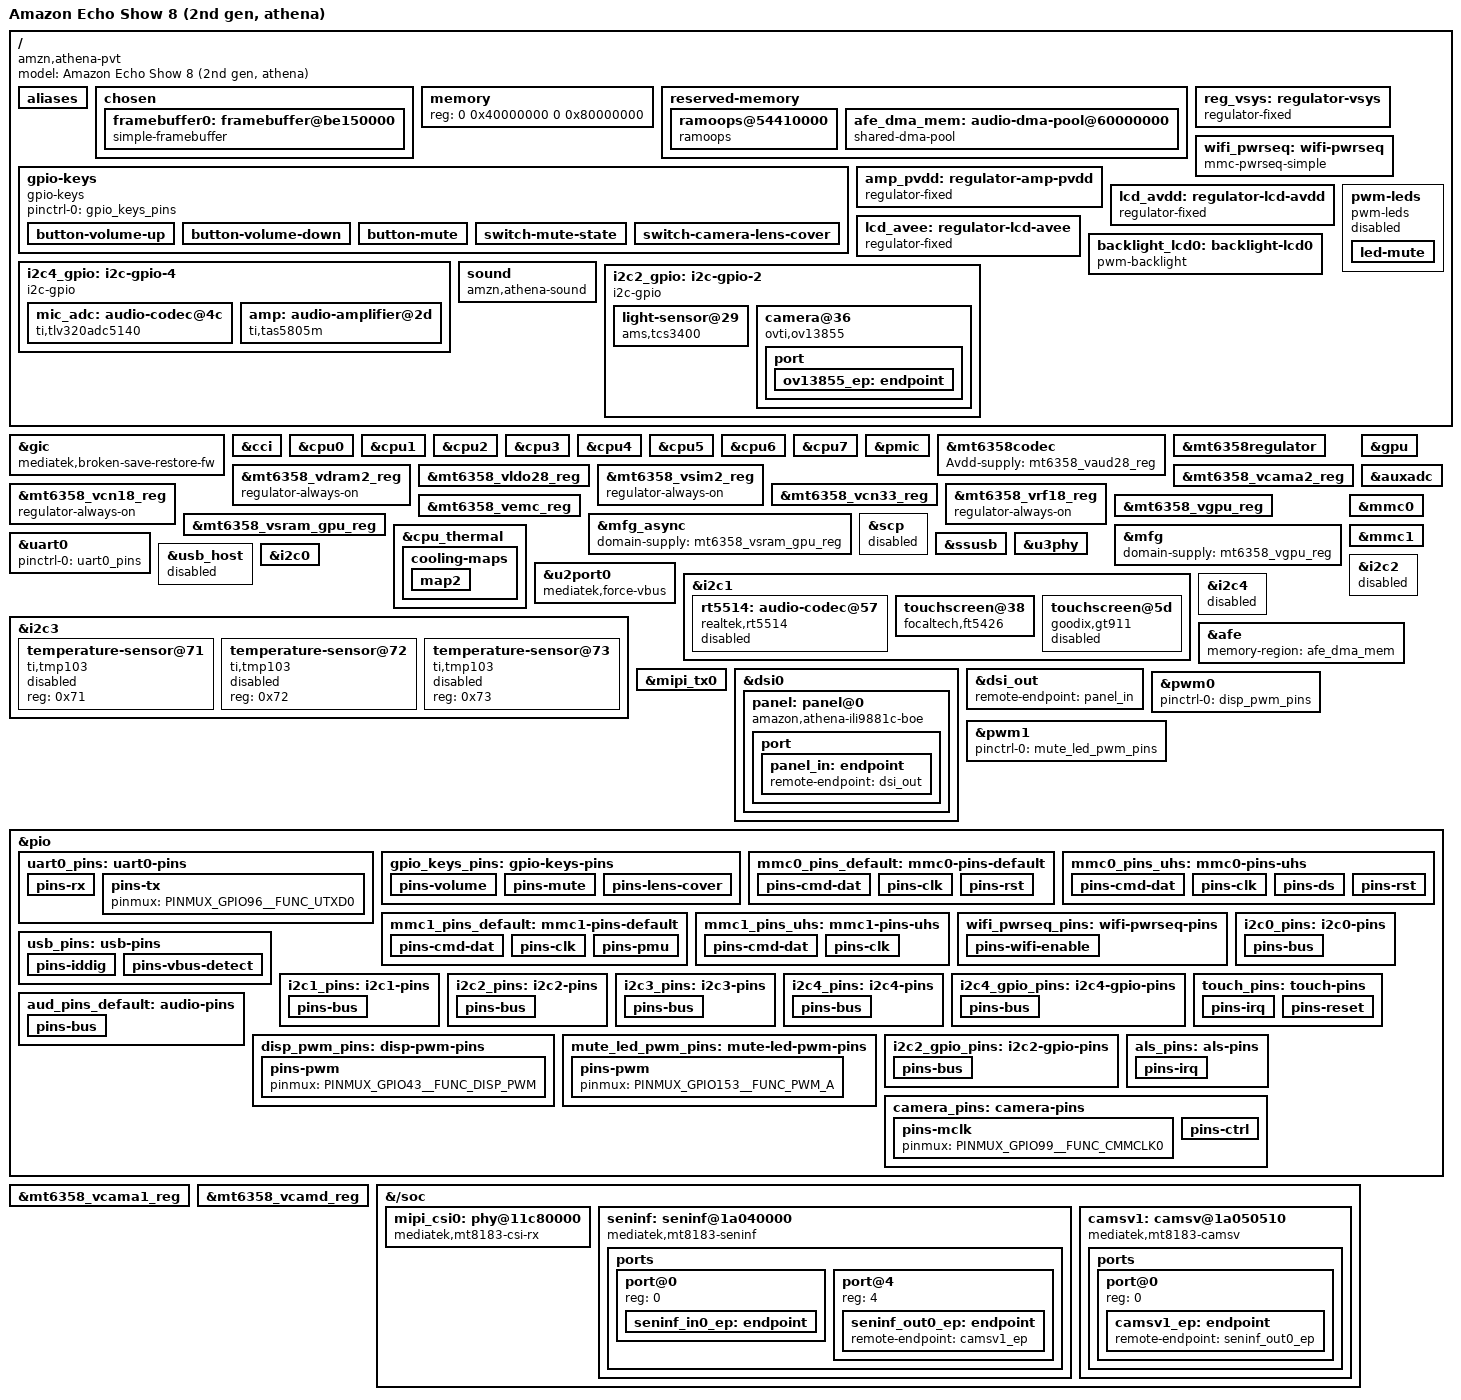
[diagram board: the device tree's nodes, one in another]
// SPDX-License-Identifier: (GPL-2.0 OR MIT)

/dts-v1/;

#include <dt-bindings/gpio/gpio.h>

#include <dt-bindings/input/input.h>

#include <dt-bindings/interrupt-controller/irq.h>

#include <dt-bindings/leds/common.h>

#include <dt-bindings/phy/phy.h>

#include "mt8183.dtsi"

#include "mt6358.dtsi"

/ {

	model = "Amazon Echo Show 8 (2nd gen, athena)";

	compatible = "amzn,athena-pvt", "amzn,athena", "mediatek,mt8183";

	aliases {

		serial0 = &uart0;

		mmc0 = &mmc0;

		mmc1 = &mmc1;

		i2c0 = &i2c0;

		i2c1 = &i2c1;

		i2c2 = &i2c2;

		i2c3 = &i2c3;

		i2c4 = &i2c4_gpio;

	};

	chosen {

		#address-cells = <2>;

		#size-cells = <2>;

		ranges;

		stdout-path = "serial0:921600n8";

		bootargs = "";

		framebuffer0: framebuffer@be150000 {

			compatible = "simple-framebuffer";

			reg = <0 0xbe150000 0 (800 * 1280 * 4)>;

			width = <800>;

			height = <1280>;

			stride = <(800 * 4)>;

			format = "a8r8g8b8";

			status = "okay";

		};

	};

	memory {

		device_type = "memory";

		reg = <0 0x40000000 0 0x80000000>;

	};

	reserved-memory {

		#address-cells = <2>;

		#size-cells = <2>;

		ranges;

		ramoops@54410000 {

			compatible = "ramoops";

			reg = <0 0x54410000 0 0xe0000>;

			record-size = <0x10000>;

			console-size = <0x40000>;

			pmsg-size = <0x10000>;

			ecc-size = <0>;

		};

		afe_dma_mem: audio-dma-pool@60000000 {

			compatible = "shared-dma-pool";

			reg = <0 0x60000000 0 0x100000>;

			no-map;

		};

	};

	reg_vsys: regulator-vsys {

		compatible = "regulator-fixed";

		regulator-name = "vsys";

		regulator-always-on;

		regulator-boot-on;

	};

	gpio-keys {

		compatible = "gpio-keys";

		pinctrl-names = "default";

		pinctrl-0 = <&gpio_keys_pins>;

		button-volume-up {

			label = "Volume Up";

			gpios = <&pio 93 GPIO_ACTIVE_LOW>;

			linux,code = <KEY_VOLUMEUP>;

			debounce-interval = <50>;

			wakeup-source;

		};

		button-volume-down {

			label = "Volume Down";

			gpios = <&pio 92 GPIO_ACTIVE_LOW>;

			linux,code = <KEY_VOLUMEDOWN>;

			debounce-interval = <50>;

			wakeup-source;

		};

		button-mute {

			label = "Mute";

			gpios = <&pio 168 GPIO_ACTIVE_LOW>;

			linux,code = <KEY_MICMUTE>;

			debounce-interval = <50>;

			wakeup-source;

		};

		switch-mute-state {

			label = "Mute State";

			gpios = <&pio 63 GPIO_ACTIVE_LOW>;

			linux,input-type = <EV_SW>;

			linux,code = <SW_MUTE_DEVICE>;

			debounce-interval = <50>;

		};

		switch-camera-lens-cover {

			label = "Camera Lens Cover";

			gpios = <&pio 152 GPIO_ACTIVE_LOW>;

			linux,input-type = <EV_SW>;

			linux,code = <SW_CAMERA_LENS_COVER>;

			debounce-interval = <50>;

		};

	};

	wifi_pwrseq: wifi-pwrseq {

		compatible = "mmc-pwrseq-simple";

		pinctrl-names = "default";

		pinctrl-0 = <&wifi_pwrseq_pins>;

		reset-gpios = <&pio 68 GPIO_ACTIVE_LOW>;

		post-power-on-delay-ms = <10>;

	};

	amp_pvdd: regulator-amp-pvdd {

		compatible = "regulator-fixed";

		regulator-name = "amp_pvdd";

		regulator-always-on;

		regulator-boot-on;

		vin-supply = <&reg_vsys>;

	};

	lcd_avdd: regulator-lcd-avdd {

		compatible = "regulator-fixed";

		regulator-name = "lcd_avdd";

		gpio = <&pio 176 GPIO_ACTIVE_HIGH>;

		enable-active-high;

		regulator-boot-on;

		startup-delay-us = <10000>;

		vin-supply = <&mt6358_vcama2_reg>;

	};

	lcd_avee: regulator-lcd-avee {

		compatible = "regulator-fixed";

		regulator-name = "lcd_avee";

		gpio = <&pio 175 GPIO_ACTIVE_HIGH>;

		enable-active-high;

		regulator-boot-on;

		startup-delay-us = <10000>;

		vin-supply = <&lcd_avdd>;

	};

	backlight_lcd0: backlight-lcd0 {

		compatible = "pwm-backlight";

		pwms = <&pwm0 0 500000>;

		power-supply = <&reg_vsys>;

		brightness-levels = <0 1023>;

		num-interpolated-steps = <1023>;

		default-brightness-level = <576>;

		status = "okay";

	};

	pwm-leds {

		compatible = "pwm-leds";

		status = "disabled";

		led-mute {

			color = <LED_COLOR_ID_RED>;

			function = LED_FUNCTION_MICMUTE;

			pwms = <&pwm1 0 190476>;

			active-low;

			max-brightness = <255>;

		};

	};

};

&gic {

	mediatek,broken-save-restore-fw;

};

&cci {

	proc-supply = <&mt6358_vproc12_reg>;

	sram-supply = <&mt6358_vsram_proc12_reg>;

};

&cpu0 {

	proc-supply = <&mt6358_vproc12_reg>;

	sram-supply = <&mt6358_vsram_proc12_reg>;

};

&cpu1 {

	proc-supply = <&mt6358_vproc12_reg>;

	sram-supply = <&mt6358_vsram_proc12_reg>;

};

&cpu2 {

	proc-supply = <&mt6358_vproc12_reg>;

	sram-supply = <&mt6358_vsram_proc12_reg>;

};

&cpu3 {

	proc-supply = <&mt6358_vproc12_reg>;

	sram-supply = <&mt6358_vsram_proc12_reg>;

};

&cpu4 {

	proc-supply = <&mt6358_vproc11_reg>;

	sram-supply = <&mt6358_vsram_proc11_reg>;

};

&cpu5 {

	proc-supply = <&mt6358_vproc11_reg>;

	sram-supply = <&mt6358_vsram_proc11_reg>;

};

&cpu6 {

	proc-supply = <&mt6358_vproc11_reg>;

	sram-supply = <&mt6358_vsram_proc11_reg>;

};

&cpu7 {

	proc-supply = <&mt6358_vproc11_reg>;

	sram-supply = <&mt6358_vsram_proc11_reg>;

};

&pmic {

	interrupts-extended = <&pio 182 IRQ_TYPE_LEVEL_HIGH>;

};

&mt6358codec {

	Avdd-supply = <&mt6358_vaud28_reg>;

};

&mt6358regulator {

	vsys-ldo1-supply = <&reg_vsys>;

	vsys-ldo2-supply = <&reg_vsys>;

	vsys-ldo3-supply = <&reg_vsys>;

	vsys-vcore-supply = <&reg_vsys>;

	vsys-vdram1-supply = <&reg_vsys>;

	vsys-vgpu-supply = <&reg_vsys>;

	vsys-vmodem-supply = <&reg_vsys>;

	vsys-vpa-supply = <&reg_vsys>;

	vsys-vproc11-supply = <&reg_vsys>;

	vsys-vproc12-supply = <&reg_vsys>;

	vsys-vs1-supply = <&reg_vsys>;

	vsys-vs2-supply = <&reg_vsys>;

	vs1-ldo1-supply = <&mt6358_vs1_reg>;

	vs2-ldo1-supply = <&mt6358_vdram1_reg>;

	vs2-ldo2-supply = <&mt6358_vs2_reg>;

	vs2-ldo3-supply = <&mt6358_vs2_reg>;

	vs2-ldo4-supply = <&mt6358_vs2_reg>;

};

&mt6358_vdram2_reg {

	regulator-always-on;

};

&mt6358_vldo28_reg {

	regulator-min-microvolt = <3000000>;

	regulator-max-microvolt = <3000000>;

	regulator-always-on;

};

&mt6358_vsim2_reg {

	regulator-always-on;

};

&mt6358_vcama2_reg {

	regulator-min-microvolt = <1800000>;

	regulator-max-microvolt = <1800000>;

};

&mt6358_vcn18_reg {

	regulator-always-on;

};

&mt6358_vcn33_reg {

	regulator-min-microvolt = <3300000>;

	regulator-max-microvolt = <3300000>;

	regulator-always-on;

};

&mt6358_vrf18_reg {

	regulator-always-on;

};

&mt6358_vemc_reg {

	regulator-min-microvolt = <3000000>;

	regulator-max-microvolt = <3000000>;

};

&mt6358_vgpu_reg {

	regulator-min-microvolt = <625000>;

	regulator-max-microvolt = <900000>;

	regulator-coupled-with = <&mt6358_vsram_gpu_reg>;

	regulator-coupled-max-spread = <100000>;

};

&mt6358_vsram_gpu_reg {

	regulator-min-microvolt = <850000>;

	regulator-max-microvolt = <1000000>;

	regulator-coupled-with = <&mt6358_vgpu_reg>;

	regulator-coupled-max-spread = <100000>;

};

&mfg_async {

	domain-supply = <&mt6358_vsram_gpu_reg>;

};

&mfg {

	domain-supply = <&mt6358_vgpu_reg>;

};

&gpu {

	mali-supply = <&mt6358_vgpu_reg>;

	#cooling-cells = <2>;

	dynamic-power-coefficient = <1500>;

	status = "okay";

};

&cpu_thermal {

	cooling-maps {

		map2 {

			trip = <&target>;

			cooling-device = <&gpu THERMAL_NO_LIMIT THERMAL_NO_LIMIT>;

			contribution = <1024>;

		};

	};

};

&auxadc {

	status = "okay";

};

&uart0 {

	pinctrl-names = "default";

	pinctrl-0 = <&uart0_pins>;

	status = "okay";

};

&mmc0 {

	pinctrl-names = "default", "state_uhs";

	pinctrl-0 = <&mmc0_pins_default>;

	pinctrl-1 = <&mmc0_pins_uhs>;

	bus-width = <8>;

	max-frequency = <200000000>;

	cap-mmc-highspeed;

	mmc-ddr-1_8v;

	mmc-hs200-1_8v;

	cap-mmc-hw-reset;

	no-sdio;

	no-sd;

	non-removable;

	vmmc-supply = <&mt6358_vemc_reg>;

	vqmmc-supply = <&mt6358_vio18_reg>;

	assigned-clocks = <&topckgen CLK_TOP_MUX_MSDC50_0>;

	assigned-clock-parents = <&topckgen CLK_TOP_MSDCPLL_CK>;

	status = "okay";

};

&scp {

	/delete-property/ memory-region;

	status = "disabled";

};

&mmc1 {

	pinctrl-names = "default", "state_uhs";

	pinctrl-0 = <&mmc1_pins_default>;

	pinctrl-1 = <&mmc1_pins_uhs>;

	bus-width = <4>;

	max-frequency = <200000000>;

	cap-sd-highspeed;

	sd-uhs-sdr50;

	sd-uhs-sdr104;

	cap-sdio-irq;

	keep-power-in-suspend;

	wakeup-source;

	non-removable;

	no-mmc;

	no-sd;

	mmc-pwrseq = <&wifi_pwrseq>;

	vmmc-supply = <&mt6358_vmch_reg>;

	vqmmc-supply = <&mt6358_vmc_reg>;

	assigned-clocks = <&topckgen CLK_TOP_MUX_MSDC30_1>;

	assigned-clock-parents = <&topckgen CLK_TOP_MSDCPLL_D2>;

	status = "okay";

};

&ssusb {

	dr_mode = "peripheral";

	maximum-speed = "high-speed";

	mediatek,u3p-dis-msk = <1>;

	mediatek,force-vbus;

	vusb33-supply = <&mt6358_vusb_reg>;

	pinctrl-names = "default";

	pinctrl-0 = <&usb_pins>;

	status = "okay";

};

&usb_host {

	status = "disabled";

};

&u2port0 {

	mediatek,force-vbus;

};

&u3phy {

	status = "okay";

};

&i2c0 {

	pinctrl-names = "default";

	pinctrl-0 = <&i2c0_pins>;

	clock-frequency = <400000>;

	status = "okay";

};

&i2c1 {

	pinctrl-names = "default";

	pinctrl-0 = <&i2c1_pins>;

	clock-frequency = <400000>;

	status = "okay";

	rt5514: audio-codec@57 {

		compatible = "realtek,rt5514";

		reg = <0x57>;

		interrupts-extended = <&pio 4 IRQ_TYPE_LEVEL_HIGH>;

		#sound-dai-cells = <0>;

		status = "disabled";

	};

	touchscreen@38 {

		compatible = "focaltech,ft5426";

		reg = <0x38>;

		pinctrl-names = "default";

		pinctrl-0 = <&touch_pins>;

		interrupts-extended = <&pio 10 IRQ_TYPE_EDGE_FALLING>;

		reset-gpios = <&pio 158 GPIO_ACTIVE_LOW>;

		vcc-supply = <&mt6358_vmch_reg>;

		touchscreen-size-x = <1280>;

		touchscreen-size-y = <800>;

	};

	touchscreen@5d {

		compatible = "goodix,gt911";

		reg = <0x5d>;

		interrupts-extended = <&pio 10 IRQ_TYPE_EDGE_FALLING>;

		irq-gpios = <&pio 10 GPIO_ACTIVE_HIGH>;

		reset-gpios = <&pio 158 GPIO_ACTIVE_HIGH>;

		AVDD28-supply = <&mt6358_vmch_reg>;

		touchscreen-size-x = <800>;

		touchscreen-size-y = <1280>;

		status = "disabled";

	};

};

&i2c2 {

	pinctrl-names = "default";

	pinctrl-0 = <&i2c2_pins>;

	clock-frequency = <400000>;

	status = "okay";

};

&i2c3 {

	pinctrl-names = "default";

	pinctrl-0 = <&i2c3_pins>;

	clock-frequency = <400000>;

	status = "okay";

	temperature-sensor@71 {

		compatible = "ti,tmp103";

		reg = <0x71>;

		status = "disabled";

	};

	temperature-sensor@72 {

		compatible = "ti,tmp103";

		reg = <0x72>;

		status = "disabled";

	};

	temperature-sensor@73 {

		compatible = "ti,tmp103";

		reg = <0x73>;

		status = "disabled";

	};

};

&i2c4 {

	status = "disabled";

};

/ {

	i2c4_gpio: i2c-gpio-4 {

		compatible = "i2c-gpio";

		pinctrl-names = "default";

		pinctrl-0 = <&i2c4_gpio_pins>;

		sda-gpios = <&pio 106 (GPIO_ACTIVE_HIGH | GPIO_OPEN_DRAIN)>;

		scl-gpios = <&pio 105 (GPIO_ACTIVE_HIGH | GPIO_OPEN_DRAIN)>;

		i2c-gpio,delay-us = <2>;

		#address-cells = <1>;

		#size-cells = <0>;

		mic_adc: audio-codec@4c {

			compatible = "ti,tlv320adc5140";

			reg = <0x4c>;

			reset-gpios = <&pio 166 GPIO_ACTIVE_HIGH>;

			#sound-dai-cells = <0>;

		};

		amp: audio-amplifier@2d {

			compatible = "ti,tas5805m";

			reg = <0x2d>;

			pdn-gpios = <&pio 37 GPIO_ACTIVE_HIGH>;

			pvdd-supply = <&amp_pvdd>;

			ti,dsp-config-name = "athena";

			amazon,athena-dsp-config = /incbin/("mt8183-amazon-athena-dsp-slot.bin");

			#sound-dai-cells = <0>;

			status = "okay";

		};

	};

};

&afe {

	memory-region = <&afe_dma_mem>;

};

/ {

	sound: sound {

		compatible = "amzn,athena-sound";

		mediatek,platform = <&afe>;

		mediatek,audio-codec = <&amp>, <&mic_adc>;

		pinctrl-names = "default";

		pinctrl-0 = <&aud_pins_default>;

	};

};

&mipi_tx0 {

	status = "okay";

};

&dsi0 {

	#address-cells = <1>;

	#size-cells = <0>;

	status = "okay";

	panel: panel@0 {

		compatible = "amazon,athena-ili9881c-boe", "ilitek,ili9881c";

		reg = <0>;

		power-supply = <&lcd_avee>;

		vccio-supply = <&mt6358_vcama2_reg>;

		vdd-supply = <&lcd_avee>;

		reset-gpios = <&pio 45 GPIO_ACTIVE_LOW>;

		backlight = <&backlight_lcd0>;

		rotation = <270>;

		port {

			panel_in: endpoint {

				remote-endpoint = <&dsi_out>;

			};

		};

	};

};

&dsi_out {

	remote-endpoint = <&panel_in>;

};

&pwm0 {

	pinctrl-names = "default";

	pinctrl-0 = <&disp_pwm_pins>;

};

&pwm1 {

	pinctrl-names = "default";

	pinctrl-0 = <&mute_led_pwm_pins>;

};

&pio {

	uart0_pins: uart0-pins {

		pins-rx {

			pinmux = <PINMUX_GPIO95__FUNC_URXD0>;

			input-enable;

			bias-pull-up;

		};

		pins-tx {

			pinmux = <PINMUX_GPIO96__FUNC_UTXD0>;

		};

	};

	gpio_keys_pins: gpio-keys-pins {

		pins-volume {

			pinmux = <PINMUX_GPIO92__FUNC_GPIO92>,

				 <PINMUX_GPIO93__FUNC_GPIO93>;

			input-enable;

			bias-pull-up = <MTK_PUPD_SET_R1R0_01>;

		};

		pins-mute {

			pinmux = <PINMUX_GPIO63__FUNC_GPIO63>,

				 <PINMUX_GPIO168__FUNC_GPIO168>;

			input-enable;

			bias-disable;

		};

		pins-lens-cover {

			pinmux = <PINMUX_GPIO152__FUNC_GPIO152>;

			input-enable;

		};

	};

	mmc0_pins_default: mmc0-pins-default {

		pins-cmd-dat {

			pinmux = <PINMUX_GPIO123__FUNC_MSDC0_DAT0>,

				 <PINMUX_GPIO128__FUNC_MSDC0_DAT1>,

				 <PINMUX_GPIO125__FUNC_MSDC0_DAT2>,

				 <PINMUX_GPIO132__FUNC_MSDC0_DAT3>,

				 <PINMUX_GPIO126__FUNC_MSDC0_DAT4>,

				 <PINMUX_GPIO129__FUNC_MSDC0_DAT5>,

				 <PINMUX_GPIO127__FUNC_MSDC0_DAT6>,

				 <PINMUX_GPIO130__FUNC_MSDC0_DAT7>,

				 <PINMUX_GPIO122__FUNC_MSDC0_CMD>;

			input-enable;

			drive-strength = <MTK_DRIVE_14mA>;

			mediatek,pull-up-adv = <1>;

		};

		pins-clk {

			pinmux = <PINMUX_GPIO124__FUNC_MSDC0_CLK>;

			drive-strength = <MTK_DRIVE_14mA>;

			mediatek,pull-down-adv = <2>;

		};

		pins-rst {

			pinmux = <PINMUX_GPIO133__FUNC_MSDC0_RSTB>;

			drive-strength = <MTK_DRIVE_14mA>;

			mediatek,pull-down-adv = <1>;

		};

	};

	mmc0_pins_uhs: mmc0-pins-uhs {

		pins-cmd-dat {

			pinmux = <PINMUX_GPIO123__FUNC_MSDC0_DAT0>,

				 <PINMUX_GPIO128__FUNC_MSDC0_DAT1>,

				 <PINMUX_GPIO125__FUNC_MSDC0_DAT2>,

				 <PINMUX_GPIO132__FUNC_MSDC0_DAT3>,

				 <PINMUX_GPIO126__FUNC_MSDC0_DAT4>,

				 <PINMUX_GPIO129__FUNC_MSDC0_DAT5>,

				 <PINMUX_GPIO127__FUNC_MSDC0_DAT6>,

				 <PINMUX_GPIO130__FUNC_MSDC0_DAT7>,

				 <PINMUX_GPIO122__FUNC_MSDC0_CMD>;

			input-enable;

			drive-strength = <MTK_DRIVE_14mA>;

			mediatek,pull-up-adv = <1>;

		};

		pins-clk {

			pinmux = <PINMUX_GPIO124__FUNC_MSDC0_CLK>;

			drive-strength = <MTK_DRIVE_14mA>;

			mediatek,pull-down-adv = <2>;

		};

		pins-ds {

			pinmux = <PINMUX_GPIO131__FUNC_MSDC0_DSL>;

			drive-strength = <MTK_DRIVE_14mA>;

			mediatek,pull-down-adv = <2>;

		};

		pins-rst {

			pinmux = <PINMUX_GPIO133__FUNC_MSDC0_RSTB>;

			drive-strength = <MTK_DRIVE_14mA>;

			mediatek,pull-up-adv = <1>;

		};

	};

	mmc1_pins_default: mmc1-pins-default {

		pins-cmd-dat {

			pinmux = <PINMUX_GPIO31__FUNC_MSDC1_CMD>,

				 <PINMUX_GPIO32__FUNC_MSDC1_DAT0>,

				 <PINMUX_GPIO34__FUNC_MSDC1_DAT1>,

				 <PINMUX_GPIO33__FUNC_MSDC1_DAT2>,

				 <PINMUX_GPIO30__FUNC_MSDC1_DAT3>;

			input-enable;

			mediatek,pull-up-adv = <2>;

		};

		pins-clk {

			pinmux = <PINMUX_GPIO29__FUNC_MSDC1_CLK>;

			input-enable;

			mediatek,pull-down-adv = <2>;

		};

		pins-pmu {

			pinmux = <PINMUX_GPIO160__FUNC_GPIO160>;

			output-high;

		};

	};

	mmc1_pins_uhs: mmc1-pins-uhs {

		pins-cmd-dat {

			pinmux = <PINMUX_GPIO31__FUNC_MSDC1_CMD>,

				 <PINMUX_GPIO32__FUNC_MSDC1_DAT0>,

				 <PINMUX_GPIO34__FUNC_MSDC1_DAT1>,

				 <PINMUX_GPIO33__FUNC_MSDC1_DAT2>,

				 <PINMUX_GPIO30__FUNC_MSDC1_DAT3>;

			drive-strength = <6>;

			input-enable;

			mediatek,pull-up-adv = <2>;

		};

		pins-clk {

			pinmux = <PINMUX_GPIO29__FUNC_MSDC1_CLK>;

			drive-strength = <8>;

			mediatek,pull-down-adv = <2>;

			input-enable;

		};

	};

	wifi_pwrseq_pins: wifi-pwrseq-pins {

		pins-wifi-enable {

			pinmux = <PINMUX_GPIO68__FUNC_GPIO68>;

			output-low;

		};

	};

	usb_pins: usb-pins {

		pins-iddig {

			pinmux = <PINMUX_GPIO41__FUNC_IDDIG>;

			input-enable;

			bias-pull-up = <MTK_PUPD_SET_R1R0_01>;

		};

		pins-vbus-detect {

			pinmux = <PINMUX_GPIO165__FUNC_GPIO165>;

			input-enable;

			bias-disable;

		};

	};

	i2c0_pins: i2c0-pins {

		pins-bus {

			pinmux = <PINMUX_GPIO82__FUNC_SDA0>,

				 <PINMUX_GPIO83__FUNC_SCL0>;

			mediatek,pull-up-adv = <3>;

		};

	};

	i2c1_pins: i2c1-pins {

		pins-bus {

			pinmux = <PINMUX_GPIO81__FUNC_SDA1>,

				 <PINMUX_GPIO84__FUNC_SCL1>;

			mediatek,pull-up-adv = <3>;

		};

	};

	i2c2_pins: i2c2-pins {

		pins-bus {

			pinmux = <PINMUX_GPIO103__FUNC_SCL2>,

				 <PINMUX_GPIO104__FUNC_SDA2>;

			mediatek,pull-up-adv = <3>;

		};

	};

	i2c3_pins: i2c3-pins {

		pins-bus {

			pinmux = <PINMUX_GPIO50__FUNC_SCL3>,

				 <PINMUX_GPIO51__FUNC_SDA3>;

			mediatek,pull-up-adv = <3>;

		};

	};

	i2c4_pins: i2c4-pins {

		pins-bus {

			pinmux = <PINMUX_GPIO105__FUNC_SCL4>,

				 <PINMUX_GPIO106__FUNC_SDA4>;

			mediatek,pull-up-adv = <3>;

		};

	};

	i2c4_gpio_pins: i2c4-gpio-pins {

		pins-bus {

			pinmux = <PINMUX_GPIO105__FUNC_GPIO105>,

				 <PINMUX_GPIO106__FUNC_GPIO106>;

			bias-pull-up;

		};

	};

	touch_pins: touch-pins {

		pins-irq {

			pinmux = <PINMUX_GPIO10__FUNC_GPIO10>;

			input-enable;

			bias-disable;

		};

		pins-reset {

			pinmux = <PINMUX_GPIO158__FUNC_GPIO158>;

			output-high;

		};

	};

	aud_pins_default: audio-pins {

		pins-bus {

			pinmux = <PINMUX_GPIO3__FUNC_I2S3_DO>,

				 <PINMUX_GPIO5__FUNC_I2S0_BCK>,

				 <PINMUX_GPIO6__FUNC_I2S0_LRCK>,

				 <PINMUX_GPIO7__FUNC_I2S0_DI>,

				 <PINMUX_GPIO12__FUNC_I2S2_DI2>,

				 <PINMUX_GPIO98__FUNC_I2S2_BCK>,

				 <PINMUX_GPIO101__FUNC_I2S2_LRCK>,

				 <PINMUX_GPIO170__FUNC_I2S1_BCK>,

				 <PINMUX_GPIO171__FUNC_I2S1_LRCK>,

				 <PINMUX_GPIO172__FUNC_I2S1_DO>,

				 <PINMUX_GPIO173__FUNC_I2S1_MCK>,

				 <PINMUX_GPIO174__FUNC_I2S2_DI>,

				 <PINMUX_GPIO136__FUNC_AUD_CLK_MOSI>,

				 <PINMUX_GPIO138__FUNC_AUD_DAT_MOSI0>,

				 <PINMUX_GPIO139__FUNC_AUD_DAT_MOSI1>,

				 <PINMUX_GPIO142__FUNC_AUD_DAT_MISO0>,

				 <PINMUX_GPIO143__FUNC_AUD_DAT_MISO1>;

		};

	};

	disp_pwm_pins: disp-pwm-pins {

		pins-pwm {

			pinmux = <PINMUX_GPIO43__FUNC_DISP_PWM>;

		};

	};

	mute_led_pwm_pins: mute-led-pwm-pins {

		pins-pwm {

			pinmux = <PINMUX_GPIO153__FUNC_PWM_A>;

		};

	};

};

/ {

	aliases {

		i2c2 = &i2c2_gpio;

	};

	i2c2_gpio: i2c-gpio-2 {

		compatible = "i2c-gpio";

		pinctrl-names = "default";

		pinctrl-0 = <&i2c2_gpio_pins>;

		sda-gpios = <&pio 104 (GPIO_ACTIVE_HIGH | GPIO_OPEN_DRAIN)>;

		scl-gpios = <&pio 103 (GPIO_ACTIVE_HIGH | GPIO_OPEN_DRAIN)>;

		i2c-gpio,delay-us = <2>;

		#address-cells = <1>;

		#size-cells = <0>;

		light-sensor@29 {

			compatible = "ams,tcs3400";

			reg = <0x29>;

			pinctrl-names = "default";

			pinctrl-0 = <&als_pins>;

			interrupts-extended = <&pio 9 IRQ_TYPE_EDGE_FALLING>;

		};

	};

};

&i2c2 {

	status = "disabled";

};

&pio {

	i2c2_gpio_pins: i2c2-gpio-pins {

		pins-bus {

			pinmux = <PINMUX_GPIO103__FUNC_GPIO103>,

				 <PINMUX_GPIO104__FUNC_GPIO104>;

			bias-pull-up;

		};

	};

	als_pins: als-pins {

		pins-irq {

			pinmux = <PINMUX_GPIO9__FUNC_GPIO9>;

			input-enable;

			bias-pull-up;

		};

	};

};

&mt6358_vcama1_reg {

	regulator-min-microvolt = <2800000>;

	regulator-max-microvolt = <2800000>;

};

&mt6358_vcamd_reg {

	regulator-min-microvolt = <1200000>;

	regulator-max-microvolt = <1200000>;

};

&pio {

	camera_pins: camera-pins {

		pins-mclk {

			pinmux = <PINMUX_GPIO99__FUNC_CMMCLK0>;

		};

		pins-ctrl {

			pinmux = <PINMUX_GPIO102__FUNC_GPIO102>,

				 <PINMUX_GPIO177__FUNC_GPIO177>;

			output-low;

		};

	};

};

&i2c2_gpio {

	camera@36 {

		compatible = "ovti,ov13855";

		reg = <0x36>;

		pinctrl-names = "default";

		pinctrl-0 = <&camera_pins>;

		clocks = <&topckgen CLK_TOP_MUX_CAMTG>;

		assigned-clocks = <&topckgen CLK_TOP_MUX_CAMTG>;

		assigned-clock-parents = <&topckgen CLK_TOP_UNIVP_192M_D8>;

		reset-gpios = <&pio 102 GPIO_ACTIVE_LOW>;

		powerdown-gpios = <&pio 177 GPIO_ACTIVE_LOW>;

		avdd-supply = <&mt6358_vcama1_reg>;

		dvdd-supply = <&mt6358_vcamd_reg>;

		dovdd-supply = <&mt6358_vcamio_reg>;

		orientation = <0>;

		port {

			ov13855_ep: endpoint {

				remote-endpoint = <&seninf_in0_ep>;

				clock-lanes = <0>;

				data-lanes = <1 2 3 4>;

				link-frequencies = /bits/ 64 <540000000 270000000>;

			};

		};

	};

};

&{/soc} {

	mipi_csi0: phy@11c80000 {

		compatible = "mediatek,mt8183-csi-rx";

		reg = <0 0x11c80000 0 0x2000>;

		num-lanes = <4>;

		#phy-cells = <1>;

	};

	seninf: seninf@1a040000 {

		compatible = "mediatek,mt8183-seninf";

		reg = <0 0x1a040000 0 0x8000>;

		interrupts = <GIC_SPI 251 IRQ_TYPE_LEVEL_LOW>;

		clocks = <&camsys CLK_CAM_SENINF>, <&topckgen CLK_TOP_MUX_SENINF>;

		clock-names = "camsys", "top_mux";

		power-domains = <&spm MT8183_POWER_DOMAIN_CAM>;

		phys = <&mipi_csi0 PHY_TYPE_DPHY>;

		phy-names = "csi0";

		ports {

			#address-cells = <1>;

			#size-cells = <0>;

			port@0 {

				reg = <0>;

				seninf_in0_ep: endpoint {

					remote-endpoint = <&ov13855_ep>;

					clock-lanes = <2>;

					data-lanes = <1 3 0 4>;

				};

			};

			port@4 {

				reg = <4>;

				seninf_out0_ep: endpoint {

					remote-endpoint = <&camsv1_ep>;

				};

			};

		};

	};

	camsv1: camsv@1a050510 {

		compatible = "mediatek,mt8183-camsv";

		reg = <0 0x1a050510 0 0x40>,

		      <0 0x1a050020 0 0x28>,

		      <0 0x1a050220 0 0x90>;

		interrupts = <GIC_SPI 258 IRQ_TYPE_LEVEL_LOW>;

		clocks = <&camsys CLK_CAM_CAM>, <&camsys CLK_CAM_CAMTG>, <&camsys CLK_CAM_CAMSV0>;

		clock-names = "cam", "camtg", "camsv";

		iommus = <&iommu M4U_PORT_CAM_SOCO>, <&iommu M4U_PORT_CAM_SOC1>,

			 <&iommu M4U_PORT_CAM_SOC2>, <&iommu M4U_PORT_CAM_IMGO>;

		power-domains = <&spm MT8183_POWER_DOMAIN_CAM>;

		ports {

			#address-cells = <1>;

			#size-cells = <0>;

			port@0 {

				reg = <0>;

				camsv1_ep: endpoint {

					remote-endpoint = <&seninf_out0_ep>;

				};

			};

		};

	};

};
